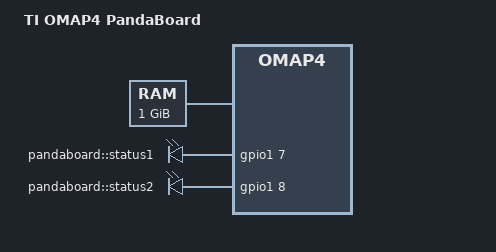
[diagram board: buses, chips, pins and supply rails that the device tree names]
/*
 * Copyright (C) 2011 Texas Instruments Incorporated - http://www.ti.com/
 *
 * This program is free software; you can redistribute it and/or modify
 * it under the terms of the GNU General Public License version 2 as
 * published by the Free Software Foundation.
 */
/dts-v1/;

/include/ "omap4.dtsi"

/ {
	model = "TI OMAP4 PandaBoard";
	compatible = "ti,omap4-panda", "ti,omap4430", "ti,omap4";

	memory {
		device_type = "memory";
		reg = <0x80000000 0x40000000>; /* 1 GB */
	};

	leds {
		compatible = "gpio-leds";
		heartbeat {
			label = "pandaboard::status1";
			gpios = <&gpio1 7 0>;
			linux,default-trigger = "heartbeat";
		};

		mmc {
			label = "pandaboard::status2";
			gpios = <&gpio1 8 0>;
			linux,default-trigger = "mmc0";
		};
	};
};
